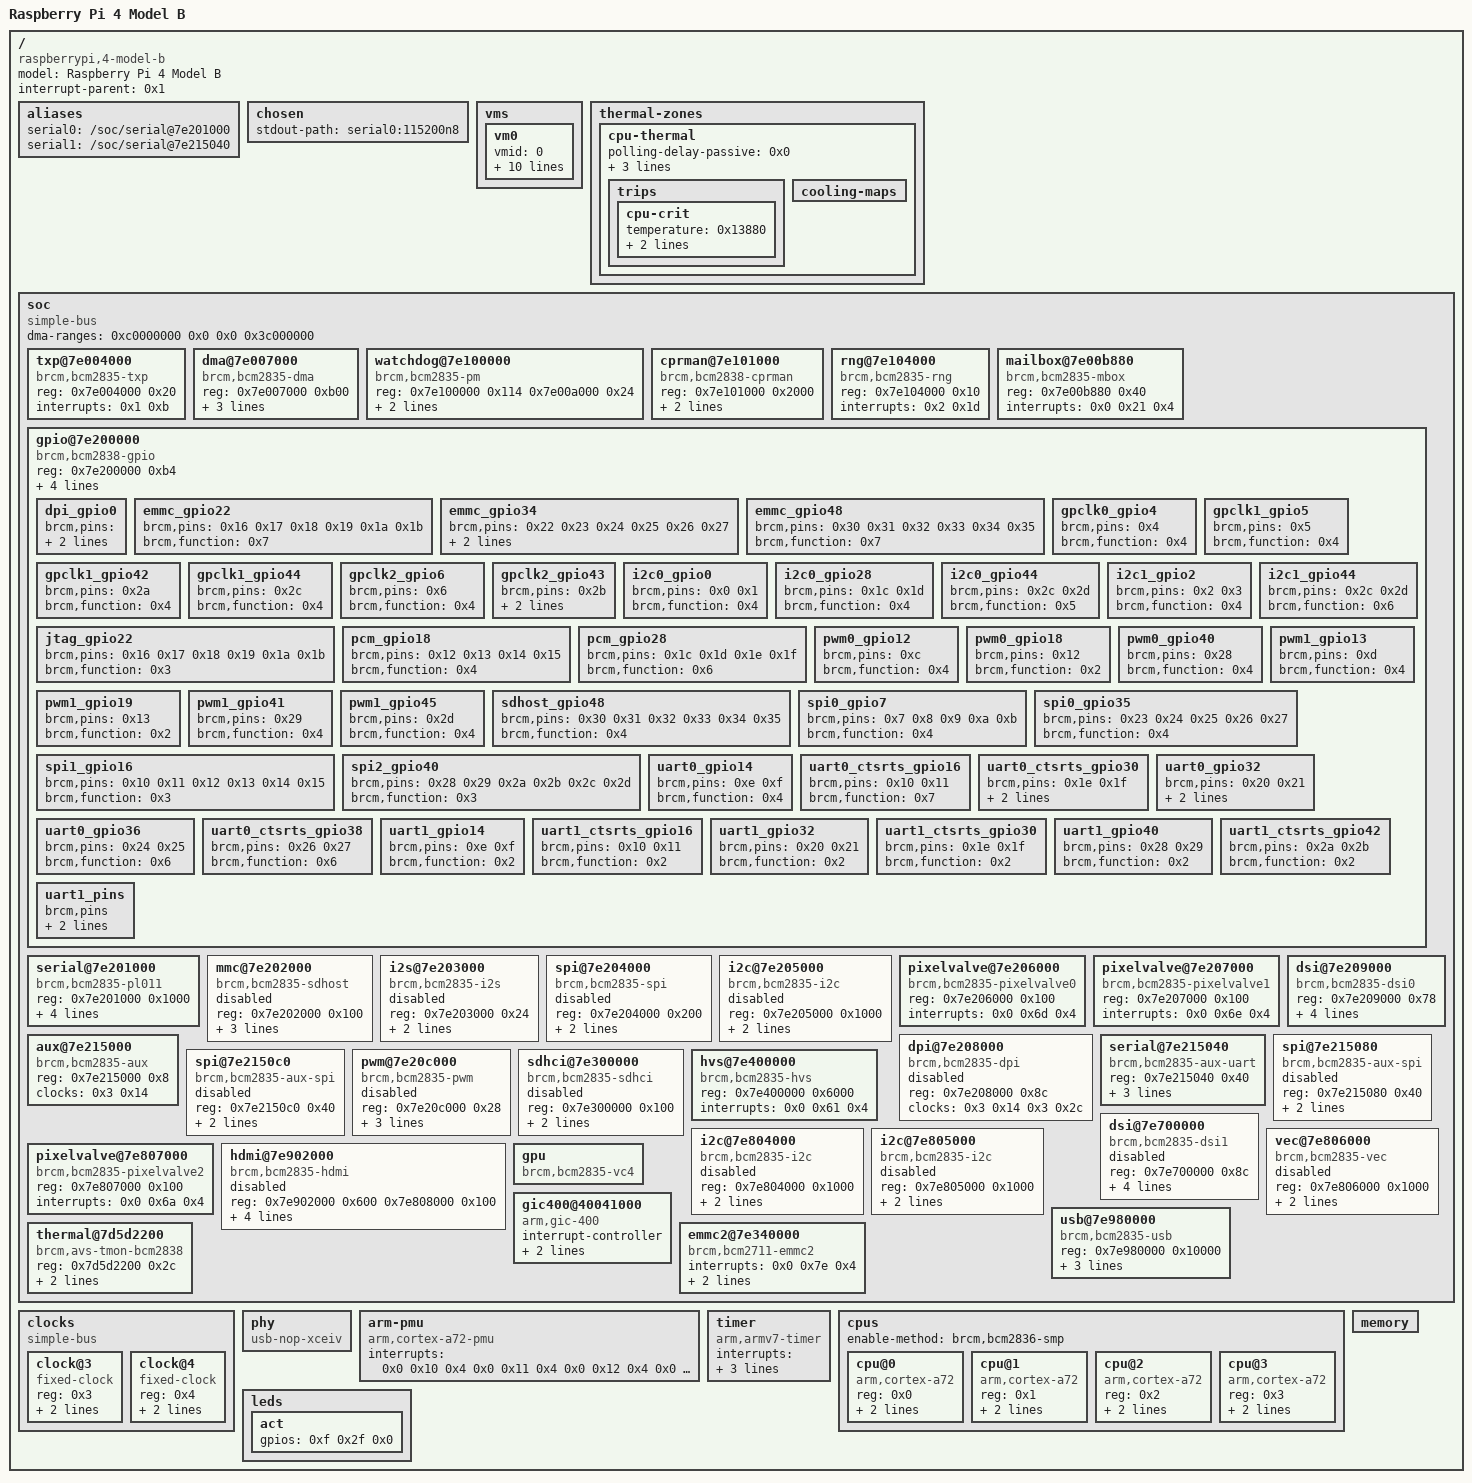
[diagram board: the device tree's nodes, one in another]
/dts-v1/;

/ {
	compatible = "raspberrypi,4-model-b", "brcm,bcm2838", "brcm,bcm2837";
	model = "Raspberry Pi 4 Model B";
	interrupt-parent = <0x1>;
	#address-cells = <0x2>;
	#size-cells = <0x1>;

	aliases {
		serial0 = "/soc/serial@7e201000";
		serial1 = "/soc/serial@7e215040";
	};

	chosen {
		stdout-path = "serial0:115200n8";
	};

	vms {
		vm0 {
			device_type = "virtual_machine";
			vmid = <0>;
			vm_name = "rpi4_linux_host";
			type = "linux";
			vcpus = <4>;
			entry = <0x0 0x00080000>;
			setup_data = <0x0 0x03e00000>;
			vcpu_affinity = <0 1 2 3>;
			memory = <0x0 0x00000000 0x0 0x37400000 0x0 0x40000000 0x0 0xbc000000>;
			cmdline = "coherent_pool=1M 8250.nr_uarts=1 earlycon=uart8250,mmio32,0xfe215040 loglevel=9 cma=64M cma=256M video=HDMI-A-1:720x576M@50,margin_left=0,margin_right=0,margin_top=0,margin_bottom=0 smsc95xx.macaddr=DC:A6:32:1C:65:A1 vc_mem.mem_base=0x3ec00000 vc_mem.mem_size=0x40000000 dwc_otg.fiq_fix_enable=0 console=ttyS0,115200 root=/dev/mmcblk0p2 rw rootfstype=ext4 rootwait rootflags=noload net.ifnames=0 loglevel=9";
		};
	};


	thermal-zones {

		cpu-thermal {
			polling-delay-passive = <0x0>;
			polling-delay = <0x3e8>;
			thermal-sensors = <0x2>;
			coefficients = <0xfffffe19 0x641b8>;

			trips {

				cpu-crit {
					temperature = <0x13880>;
					hysteresis = <0x0>;
					type = "critical";
				};
			};

			cooling-maps {
			};
		};
	};

	soc {
		compatible = "simple-bus";
		#address-cells = <0x1>;
		#size-cells = <0x1>;
		ranges = <0x7e000000 0x0 0xfe000000 0x1800000 0x7c000000 0x0 0xfc000000 0x2000000 0x40000000 0x0 0xff800000 0x800000>;
		dma-ranges = <0xc0000000 0x0 0x0 0x3c000000>;

		txp@7e004000 {
			compatible = "brcm,bcm2835-txp";
			reg = <0x7e004000 0x20>;
			interrupts = <0x1 0xb>;
		};

		dma@7e007000 {
			compatible = "brcm,bcm2835-dma";
			reg = <0x7e007000 0xb00>;
			interrupts = <0x0 0x50 0x4 0x0 0x51 0x4 0x0 0x52 0x4 0x0 0x53 0x4 0x0 0x54 0x4 0x0 0x55 0x4 0x0 0x56 0x4 0x0 0x57 0x4 0x0 0x57 0x4 0x0 0x58 0x4 0x0 0x58 0x4>;
			interrupt-names = "dma0", "dma1", "dma2", "dma3", "dma4", "dma5", "dma6", "dma7", "dma8", "dma9", "dma10";
			#dma-cells = <0x1>;
			brcm,dma-channel-mask = <0x7f5>;
			phandle = <0x9>;
		};

		watchdog@7e100000 {
			compatible = "brcm,bcm2835-pm", "brcm,bcm2835-pm-wdt";
			#power-domain-cells = <0x1>;
			#reset-cells = <0x1>;
			reg = <0x7e100000 0x114 0x7e00a000 0x24>;
			clocks = <0x3 0x15 0x3 0x1d 0x3 0x17 0x3 0x16>;
			clock-names = "v3d", "peri_image", "h264", "isp";
			system-power-controller;
		};

		cprman@7e101000 {
			compatible = "brcm,bcm2838-cprman";
			#clock-cells = <0x1>;
			reg = <0x7e101000 0x2000>;
			clocks = <0x4 0x5 0x0 0x5 0x1 0x5 0x2 0x6 0x0 0x6 0x1 0x6 0x2>;
			phandle = <0x3>;
		};

		rng@7e104000 {
			compatible = "brcm,bcm2835-rng";
			reg = <0x7e104000 0x10>;
			interrupts = <0x2 0x1d>;
		};

		mailbox@7e00b880 {
			compatible = "brcm,bcm2835-mbox";
			reg = <0x7e00b880 0x40>;
			interrupts = <0x0 0x21 0x4>;
			#mbox-cells = <0x0>;
		};

		gpio@7e200000 {
			compatible = "brcm,bcm2838-gpio", "brcm,bcm2835-gpio";
			reg = <0x7e200000 0xb4>;
			interrupts = <0x0 0x71 0x4 0x0 0x72 0x4 0x0 0x73 0x4 0x0 0x74 0x4>;
			gpio-controller;
			#gpio-cells = <0x2>;
			interrupt-controller;
			#interrupt-cells = <0x2>;
			phandle = <0xf>;

			dpi_gpio0 {
				brcm,pins = <0x0 0x1 0x2 0x3 0x4 0x5 0x6 0x7 0x8 0x9 0xa 0xb 0xc 0xd 0xe 0xf 0x10 0x11 0x12 0x13 0x14 0x15 0x16 0x17 0x18 0x19 0x1a 0x1b>;
				brcm,function = <0x6>;
			};

			emmc_gpio22 {
				brcm,pins = <0x16 0x17 0x18 0x19 0x1a 0x1b>;
				brcm,function = <0x7>;
			};

			emmc_gpio34 {
				brcm,pins = <0x22 0x23 0x24 0x25 0x26 0x27>;
				brcm,function = <0x7>;
				brcm,pull = <0x0 0x2 0x2 0x2 0x2 0x2>;
			};

			emmc_gpio48 {
				brcm,pins = <0x30 0x31 0x32 0x33 0x34 0x35>;
				brcm,function = <0x7>;
			};

			gpclk0_gpio4 {
				brcm,pins = <0x4>;
				brcm,function = <0x4>;
			};

			gpclk1_gpio5 {
				brcm,pins = <0x5>;
				brcm,function = <0x4>;
			};

			gpclk1_gpio42 {
				brcm,pins = <0x2a>;
				brcm,function = <0x4>;
			};

			gpclk1_gpio44 {
				brcm,pins = <0x2c>;
				brcm,function = <0x4>;
			};

			gpclk2_gpio6 {
				brcm,pins = <0x6>;
				brcm,function = <0x4>;
			};

			gpclk2_gpio43 {
				brcm,pins = <0x2b>;
				brcm,function = <0x4>;
				brcm,pull = <0x0>;
				phandle = <0x8>;
			};

			i2c0_gpio0 {
				brcm,pins = <0x0 0x1>;
				brcm,function = <0x4>;
			};

			i2c0_gpio28 {
				brcm,pins = <0x1c 0x1d>;
				brcm,function = <0x4>;
			};

			i2c0_gpio44 {
				brcm,pins = <0x2c 0x2d>;
				brcm,function = <0x5>;
			};

			i2c1_gpio2 {
				brcm,pins = <0x2 0x3>;
				brcm,function = <0x4>;
			};

			i2c1_gpio44 {
				brcm,pins = <0x2c 0x2d>;
				brcm,function = <0x6>;
			};

			jtag_gpio22 {
				brcm,pins = <0x16 0x17 0x18 0x19 0x1a 0x1b>;
				brcm,function = <0x3>;
			};

			pcm_gpio18 {
				brcm,pins = <0x12 0x13 0x14 0x15>;
				brcm,function = <0x4>;
			};

			pcm_gpio28 {
				brcm,pins = <0x1c 0x1d 0x1e 0x1f>;
				brcm,function = <0x6>;
			};

			pwm0_gpio12 {
				brcm,pins = <0xc>;
				brcm,function = <0x4>;
			};

			pwm0_gpio18 {
				brcm,pins = <0x12>;
				brcm,function = <0x2>;
			};

			pwm0_gpio40 {
				brcm,pins = <0x28>;
				brcm,function = <0x4>;
			};

			pwm1_gpio13 {
				brcm,pins = <0xd>;
				brcm,function = <0x4>;
			};

			pwm1_gpio19 {
				brcm,pins = <0x13>;
				brcm,function = <0x2>;
			};

			pwm1_gpio41 {
				brcm,pins = <0x29>;
				brcm,function = <0x4>;
			};

			pwm1_gpio45 {
				brcm,pins = <0x2d>;
				brcm,function = <0x4>;
			};

			sdhost_gpio48 {
				brcm,pins = <0x30 0x31 0x32 0x33 0x34 0x35>;
				brcm,function = <0x4>;
			};

			spi0_gpio7 {
				brcm,pins = <0x7 0x8 0x9 0xa 0xb>;
				brcm,function = <0x4>;
			};

			spi0_gpio35 {
				brcm,pins = <0x23 0x24 0x25 0x26 0x27>;
				brcm,function = <0x4>;
			};

			spi1_gpio16 {
				brcm,pins = <0x10 0x11 0x12 0x13 0x14 0x15>;
				brcm,function = <0x3>;
			};

			spi2_gpio40 {
				brcm,pins = <0x28 0x29 0x2a 0x2b 0x2c 0x2d>;
				brcm,function = <0x3>;
			};

			uart0_gpio14 {
				brcm,pins = <0xe 0xf>;
				brcm,function = <0x4>;
			};

			uart0_ctsrts_gpio16 {
				brcm,pins = <0x10 0x11>;
				brcm,function = <0x7>;
			};

			uart0_ctsrts_gpio30 {
				brcm,pins = <0x1e 0x1f>;
				brcm,function = <0x7>;
				brcm,pull = <0x2 0x0>;
			};

			uart0_gpio32 {
				brcm,pins = <0x20 0x21>;
				brcm,function = <0x7>;
				brcm,pull = <0x0 0x2>;
				phandle = <0x7>;
			};

			uart0_gpio36 {
				brcm,pins = <0x24 0x25>;
				brcm,function = <0x6>;
			};

			uart0_ctsrts_gpio38 {
				brcm,pins = <0x26 0x27>;
				brcm,function = <0x6>;
			};

			uart1_gpio14 {
				brcm,pins = <0xe 0xf>;
				brcm,function = <0x2>;
			};

			uart1_ctsrts_gpio16 {
				brcm,pins = <0x10 0x11>;
				brcm,function = <0x2>;
			};

			uart1_gpio32 {
				brcm,pins = <0x20 0x21>;
				brcm,function = <0x2>;
			};

			uart1_ctsrts_gpio30 {
				brcm,pins = <0x1e 0x1f>;
				brcm,function = <0x2>;
			};

			uart1_gpio40 {
				brcm,pins = <0x28 0x29>;
				brcm,function = <0x2>;
			};

			uart1_ctsrts_gpio42 {
				brcm,pins = <0x2a 0x2b>;
				brcm,function = <0x2>;
			};

			uart1_pins {
				brcm,pins;
				brcm,function;
				brcm,pull;
				phandle = <0xb>;
			};
		};

		serial@7e201000 {
			compatible = "brcm,bcm2835-pl011", "arm,pl011", "arm,primecell";
			reg = <0x7e201000 0x1000>;
			interrupts = <0x0 0x79 0x4>;
			clocks = <0x3 0x13 0x3 0x14>;
			clock-names = "uartclk", "apb_pclk";
			arm,primecell-periphid = <0x241011>;
			pinctrl-names = "default";
			pinctrl-0 = <0x7 0x8>;
			status = "okay";
		};

		mmc@7e202000 {
			compatible = "brcm,bcm2835-sdhost";
			reg = <0x7e202000 0x100>;
			interrupts = <0x0 0x78 0x4>;
			clocks = <0x3 0x14>;
			dmas = <0x9 0xd>;
			dma-names = "rx-tx";
			status = "disabled";
		};

		i2s@7e203000 {
			compatible = "brcm,bcm2835-i2s";
			reg = <0x7e203000 0x24>;
			clocks = <0x3 0x1f>;
			dmas = <0x9 0x2 0x9 0x3>;
			dma-names = "tx", "rx";
			status = "disabled";
		};

		spi@7e204000 {
			compatible = "brcm,bcm2835-spi";
			reg = <0x7e204000 0x200>;
			interrupts = <0x0 0x76 0x4>;
			clocks = <0x3 0x14>;
			#address-cells = <0x1>;
			#size-cells = <0x0>;
			status = "disabled";
		};

		i2c@7e205000 {
			compatible = "brcm,bcm2835-i2c";
			reg = <0x7e205000 0x1000>;
			interrupts = <0x0 0x75 0x4>;
			clocks = <0x3 0x14>;
			#address-cells = <0x1>;
			#size-cells = <0x0>;
			status = "disabled";
		};

		pixelvalve@7e206000 {
			compatible = "brcm,bcm2835-pixelvalve0";
			reg = <0x7e206000 0x100>;
			interrupts = <0x0 0x6d 0x4>;
		};

		pixelvalve@7e207000 {
			compatible = "brcm,bcm2835-pixelvalve1";
			reg = <0x7e207000 0x100>;
			interrupts = <0x0 0x6e 0x4>;
		};

		dpi@7e208000 {
			compatible = "brcm,bcm2835-dpi";
			reg = <0x7e208000 0x8c>;
			clocks = <0x3 0x14 0x3 0x2c>;
			clock-names = "core", "pixel";
			#address-cells = <0x1>;
			#size-cells = <0x0>;
			status = "disabled";
		};

		dsi@7e209000 {
			compatible = "brcm,bcm2835-dsi0";
			reg = <0x7e209000 0x78>;
			interrupts = <0x0 0x64 0x4>;
			#address-cells = <0x1>;
			#size-cells = <0x0>;
			#clock-cells = <0x1>;
			clocks = <0x3 0x20 0x3 0x2f 0x3 0x31>;
			clock-names = "phy", "escape", "pixel";
			clock-output-names = "dsi0_byte", "dsi0_ddr2", "dsi0_ddr";
			phandle = <0x5>;
		};

		aux@7e215000 {
			compatible = "brcm,bcm2835-aux";
			#clock-cells = <0x1>;
			reg = <0x7e215000 0x8>;
			clocks = <0x3 0x14>;
			phandle = <0xa>;
		};

		serial@7e215040 {
			compatible = "brcm,bcm2835-aux-uart";
			reg = <0x7e215040 0x40>;
			interrupts = <0x0 0x5d 0x4>;
			clocks = <0xa 0x0>;
			status = "okay";
			pinctrl-names = "default";
			pinctrl-0 = <0xb>;
		};

		spi@7e215080 {
			compatible = "brcm,bcm2835-aux-spi";
			reg = <0x7e215080 0x40>;
			interrupts = <0x0 0x5d 0x4>;
			clocks = <0xa 0x1>;
			#address-cells = <0x1>;
			#size-cells = <0x0>;
			status = "disabled";
		};

		spi@7e2150c0 {
			compatible = "brcm,bcm2835-aux-spi";
			reg = <0x7e2150c0 0x40>;
			interrupts = <0x0 0x5d 0x4>;
			clocks = <0xa 0x2>;
			#address-cells = <0x1>;
			#size-cells = <0x0>;
			status = "disabled";
		};

		pwm@7e20c000 {
			compatible = "brcm,bcm2835-pwm";
			reg = <0x7e20c000 0x28>;
			clocks = <0x3 0x1e>;
			assigned-clocks = <0x3 0x1e>;
			assigned-clock-rates = <0x989680>;
			#pwm-cells = <0x2>;
			status = "disabled";
		};

		sdhci@7e300000 {
			compatible = "brcm,bcm2835-sdhci";
			reg = <0x7e300000 0x100>;
			interrupts = <0x2 0x1e>;
			clocks = <0x3 0x1c>;
			status = "disabled";
		};

		hvs@7e400000 {
			compatible = "brcm,bcm2835-hvs";
			reg = <0x7e400000 0x6000>;
			interrupts = <0x0 0x61 0x4>;
		};

		dsi@7e700000 {
			compatible = "brcm,bcm2835-dsi1";
			reg = <0x7e700000 0x8c>;
			interrupts = <0x0 0x6c 0x4>;
			#address-cells = <0x1>;
			#size-cells = <0x0>;
			#clock-cells = <0x1>;
			clocks = <0x3 0x23 0x3 0x30 0x3 0x32>;
			clock-names = "phy", "escape", "pixel";
			clock-output-names = "dsi1_byte", "dsi1_ddr2", "dsi1_ddr";
			status = "disabled";
			phandle = <0x6>;
		};

		i2c@7e804000 {
			compatible = "brcm,bcm2835-i2c";
			reg = <0x7e804000 0x1000>;
			interrupts = <0x0 0x75 0x4>;
			clocks = <0x3 0x14>;
			#address-cells = <0x1>;
			#size-cells = <0x0>;
			status = "disabled";
		};

		i2c@7e805000 {
			compatible = "brcm,bcm2835-i2c";
			reg = <0x7e805000 0x1000>;
			interrupts = <0x0 0x75 0x4>;
			clocks = <0x3 0x14>;
			#address-cells = <0x1>;
			#size-cells = <0x0>;
			status = "disabled";
			phandle = <0xc>;
		};

		vec@7e806000 {
			compatible = "brcm,bcm2835-vec";
			reg = <0x7e806000 0x1000>;
			clocks = <0x3 0x18>;
			interrupts = <0x0 0x7b 0x4>;
			status = "disabled";
		};

		pixelvalve@7e807000 {
			compatible = "brcm,bcm2835-pixelvalve2";
			reg = <0x7e807000 0x100>;
			interrupts = <0x0 0x6a 0x4>;
		};

		hdmi@7e902000 {
			compatible = "brcm,bcm2835-hdmi";
			reg = <0x7e902000 0x600 0x7e808000 0x100>;
			interrupts = <0x0 0x68 0x4 0x0 0x69 0x4>;
			ddc = <0xc>;
			clocks = <0x3 0x10 0x3 0x19>;
			clock-names = "pixel", "hdmi";
			dmas = <0x9 0x11>;
			dma-names = "audio-rx";
			status = "disabled";
		};

		usb@7e980000 {
			compatible = "brcm,bcm2835-usb";
			reg = <0x7e980000 0x10000>;
			interrupts = <0x0 0x49 0x4>;
			#address-cells = <0x1>;
			#size-cells = <0x0>;
			clocks = <0xd>;
			clock-names = "otg";
			phys = <0xe>;
			phy-names = "usb2-phy";
		};

		gpu {
			compatible = "brcm,bcm2835-vc4";
		};

		gic400@40041000 {
			interrupt-controller;
			#interrupt-cells = <0x3>;
			compatible = "arm,gic-400";
			reg = <0x40041000 0x1000 0x40042000 0x2000 0x40044000 0x2000 0x40046000 0x2000>;
			phandle = <0x1>;
		};

		thermal@7d5d2200 {
			compatible = "brcm,avs-tmon-bcm2838";
			reg = <0x7d5d2200 0x2c>;
			interrupts = <0x0 0x89 0x4>;
			interrupt-names = "tmon";
			clocks = <0x3 0x1b>;
			#thermal-sensor-cells = <0x0>;
			status = "okay";
			phandle = <0x2>;
		};

		emmc2@7e340000 {
			compatible = "brcm,bcm2711-emmc2";
			status = "okay";
			interrupts = <0x0 0x7e 0x4>;
			clocks = <0x3 0x33>;
			reg = <0x7e340000 0x100>;
		};
	};

	clocks {
		compatible = "simple-bus";
		#address-cells = <0x1>;
		#size-cells = <0x0>;

		clock@3 {
			compatible = "fixed-clock";
			reg = <0x3>;
			#clock-cells = <0x0>;
			clock-output-names = "osc";
			clock-frequency = <0x337f980>;
			phandle = <0x4>;
		};

		clock@4 {
			compatible = "fixed-clock";
			reg = <0x4>;
			#clock-cells = <0x0>;
			clock-output-names = "otg";
			clock-frequency = <0x1c9c3800>;
			phandle = <0xd>;
		};
	};

	phy {
		compatible = "usb-nop-xceiv";
		#phy-cells = <0x0>;
		phandle = <0xe>;
	};

	arm-pmu {
		compatible = "arm,cortex-a72-pmu", "arm,cortex-a53-pmu";
		interrupts = <0x0 0x10 0x4 0x0 0x11 0x4 0x0 0x12 0x4 0x0 0x13 0x4>;
	};

	timer {
		compatible = "arm,armv7-timer";
		interrupts = <0x1 0xd 0xf08 0x1 0xe 0xf08 0x1 0xb 0xf08 0x1 0xa 0xf08>;
		arm,cpu-registers-not-fw-configured;
		always-on;
	};

	cpus {
		#address-cells = <0x1>;
		#size-cells = <0x0>;
		enable-method = "brcm,bcm2836-smp";

		cpu@0 {
			device_type = "cpu";
			compatible = "arm,cortex-a72";
			reg = <0x0>;
			enable-method = "spin-table";
			cpu-release-addr = <0x0 0xd8>;
		};

		cpu@1 {
			device_type = "cpu";
			compatible = "arm,cortex-a72";
			reg = <0x1>;
			enable-method = "spin-table";
			cpu-release-addr = <0x0 0xe0>;
		};

		cpu@2 {
			device_type = "cpu";
			compatible = "arm,cortex-a72";
			reg = <0x2>;
			enable-method = "spin-table";
			cpu-release-addr = <0x0 0xe8>;
		};

		cpu@3 {
			device_type = "cpu";
			compatible = "arm,cortex-a72";
			reg = <0x3>;
			enable-method = "spin-table";
			cpu-release-addr = <0x0 0xf0>;
		};
	};

	memory {
		device_type = "memory";
	};

	leds {

		act {
			gpios = <0xf 0x2f 0x0>;
		};
	};
};
